AUTOSAR XML (schema 4-2-2)
package /ComponentTypes
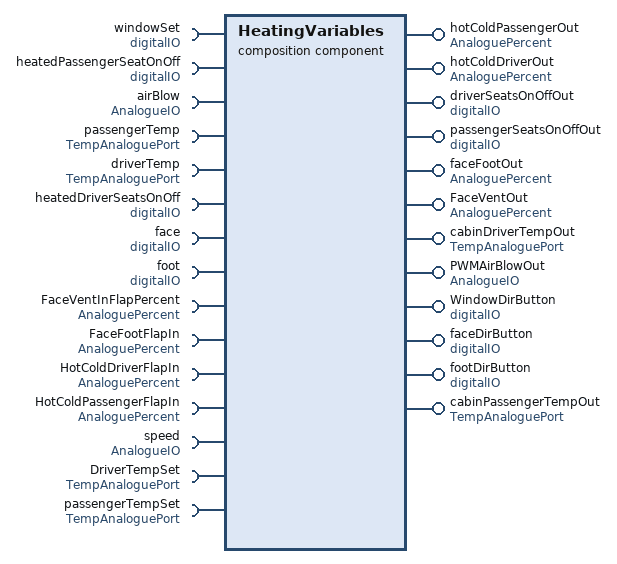
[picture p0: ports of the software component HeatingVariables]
  composition sw component type HeatingVariables
    8 x require port:
      windowSet: required-interface=digitalIO
      heatedPassengerSeatOnOff: required-interface=digitalIO
      airBlow: required-interface=AnalogueIO
      passengerTemp: required-interface=TempAnaloguePort
      driverTemp: required-interface=TempAnaloguePort
      heatedDriverSeatsOnOff: required-interface=digitalIO
      face: required-interface=digitalIO
      foot: required-interface=digitalIO
    11 x provide port:
      hotColdPassengerOut: provided-interface=AnaloguePercent
      hotColdDriverOut: provided-interface=AnaloguePercent
      driverSeatsOnOffOut: provided-interface=digitalIO
      passengerSeatsOnOffOut: provided-interface=digitalIO
      faceFootOut: provided-interface=AnaloguePercent
      FaceVentOut: provided-interface=AnaloguePercent
      cabinDriverTempOut: provided-interface=TempAnaloguePort
      PWMAirBlowOut: provided-interface=AnalogueIO
      WindowDirButton: provided-interface=digitalIO
      faceDirButton: provided-interface=digitalIO
      footDirButton: provided-interface=digitalIO
    4 x require port, all with required-interface=AnaloguePercent:
      FaceVentInFlapPercent
      FaceFootFlapIn
      HotColdDriverFlapIn
      HotColdPassengerFlapIn
    provide port cabinPassengerTempOut: provided-interface=TempAnaloguePort
    require port speed: nonqueued-receiver-com-spec=data-element=speed, required-interface=AnalogueIO
    require port DriverTempSet: required-com-specs=[data-element=tempIn, data-element=tempOut], required-interface=TempAnaloguePort
    require port passengerTempSet: required-com-specs=[data-element=tempIn, data-element=tempOut], required-interface=TempAnaloguePort
    5 x component:
      APAirBlow: type=ApAirBlow
      ApAirDirection: type=AirDirection
      ApHeatedSeats: type=ApHeatingSeats
      APDesiredTemp: type=APDesiredTemp
      APFlapDIr: type=ApFlapsDir
    delegate APAirBlow.airBlowIn <-> outer port airBlow
    delegate APAirBlow.PWMAirBlowOut <-> outer port PWMAirBlowOut
    delegate ApHeatedSeats.PassengerSeatsOnOff <-> outer port heatedPassengerSeatOnOff
    delegate ApHeatedSeats.DriverSeatsOnOff <-> outer port heatedDriverSeatsOnOff
    delegate ApHeatedSeats.driverSeatHeatOut <-> outer port driverSeatsOnOffOut
    delegate ApHeatedSeats.passengerHeatSetOut <-> outer port passengerSeatsOnOffOut
    delegate ApAirDirection.face <-> outer port face
    delegate ApAirDirection.windowSet <-> outer port windowSet
    delegate ApAirDirection.foot <-> outer port foot
    delegate ApAirDirection.WindowButtonOut <-> outer port WindowDirButton
    delegate ApAirDirection.footButtonOut <-> outer port footDirButton
    delegate ApAirDirection.FaceButtonOut <-> outer port faceDirButton
    delegate APDesiredTemp.CurrentPassengerTemp <-> outer port passengerTemp
    delegate APDesiredTemp.CurrentDriverTemp <-> outer port driverTemp
    delegate APDesiredTemp.CurrentPassengerTempOut <-> outer port cabinPassengerTempOut
    delegate APDesiredTemp.CurrentDriverTempOut <-> outer port cabinDriverTempOut
    delegate APFlapDIr.HotColdPassengerFlapIn <-> outer port HotColdPassengerFlapIn
    delegate APFlapDIr.FaceVentFlapIn <-> outer port FaceVentInFlapPercent
    delegate APFlapDIr.HotColdDriverFlapIn <-> outer port HotColdDriverFlapIn
    delegate APFlapDIr.FaceFootFlapIn <-> outer port FaceFootFlapIn
    delegate APFlapDIr.hotColdPassengerOut <-> outer port hotColdPassengerOut
    delegate APFlapDIr.FaceVentOut <-> outer port FaceVentOut
    delegate APFlapDIr.hotColdDriverOut <-> outer port hotColdDriverOut
    delegate APFlapDIr.FaceFootOut <-> outer port faceFootOut
    delegate ApHeatedSeats.currentSpeed <-> outer port speed
    delegate APDesiredTemp.PassengertemperatureSet <-> outer port passengerTempSet
    delegate APDesiredTemp.DriverTempSet <-> outer port DriverTempSet
